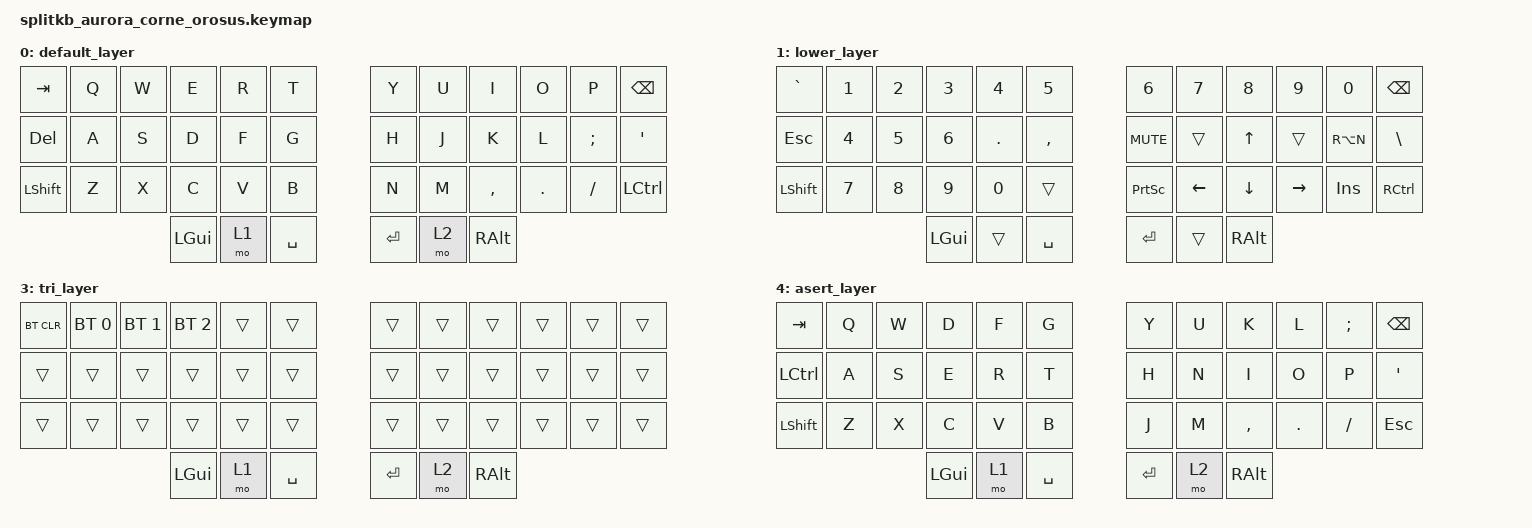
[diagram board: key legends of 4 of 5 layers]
/*
 * Copyright (c) 2020 The ZMK Contributors
 *
 * SPDX-License-Identifier: MIT
 */
 
// ------ Libraries ------------------------------------------------------------------------
#include <behaviors.dtsi>
#include <dt-bindings/zmk/keys.h>
#include <dt-bindings/zmk/outputs.h>
#include <dt-bindings/zmk/bt.h>

#define ___ &trans

// ------ main bracket ---------------------------------------------------------------------
/ {
    // -------------------------------------------------------------------------------------------------------------------------
    
    conditional_layers {
        compatible = "zmk,conditional-layers";
        tri_layer {
            if-layers = <1 2>;
            then-layer = <3>;
        };
    };
    
    // -------------------------------------------------------------------------------------------------------------------------
    keymap {
        compatible = "zmk,keymap";

        default_layer {
            bindings = <
// ┌─────────┬─────────┬─────────┬─────────┬─────────┬─────────┐   ┌─────────┬─────────┬─────────┬─────────┬─────────┬─────────┐ 
// |   TAB   |    Q    |    W    |    E    |    R    |    T    |   |    Y    |    U    |    I    |    O    |    P    |   BKSP  |
    &kp TAB   &kp Q     &kp W     &kp E     &kp R     &kp T         &kp Y     &kp U     &kp I     &kp O     &kp P     &kp BSPC
// ├─────────┼─────────┼─────────┼─────────┼─────────┼─────────┤   ├─────────┼─────────┼─────────┼─────────┼─────────┼─────────┤ 
// |  DEL    |    A    |    S    |    D    |    F    |    G    |   |    H    |    J    |    K    |    L    |    ;    |    '    |
   &kp DEL    &kp A     &kp S     &kp D     &kp F     &kp G         &kp H     &kp J     &kp K     &kp L     &kp SEMI  &kp SQT
// ├─────────┼─────────┼─────────┼─────────┼─────────┼─────────┤   ├─────────┼─────────┼─────────┼─────────┼─────────┼─────────┤ 
// |  SHFT   |    Z    |    X    |    C    |    V    |    B    |   |    N    |    M    |    ,    |    .    |    /    |   CTRL  |
   &kp LSHFT  &kp Z     &kp X     &kp C     &kp V     &kp B         &kp N     &kp M     &kp COMMA  &kp DOT   &kp FSLH  &kp LCTRL
// └─────────┴─────────┴─────────┼─────────┼─────────┼─────────┤   ├─────────┼─────────┼─────────┼─────────┴─────────┴─────────┘ 
//                               |   GUI   |  LOWER  |  SPACE  |   |  ENTER  |  RAISE  |   ALT   |
                                  &kp LGUI  &mo 1     &kp SPACE     &kp RET   &mo 2     &kp RALT
//                               └─────────┴─────────┴─────────┘   └─────────┴─────────┴─────────┘
            >;
        };
        lower_layer {
            bindings = <
// ┌─────────┬─────────┬─────────┬─────────┬─────────┬─────────┐   ┌─────────┬─────────┬─────────┬─────────┬─────────┬─────────┐ 
// |    `    |    1    |    2    |    3    |    4    |    5    |   |    6    |    7    |    8    |    9    |    0    |   BKSP  |
   &kp GRAVE  &kp N1    &kp N2    &kp N3    &kp N4    &kp N5        &kp N6    &kp N7    &kp N8    &kp N9    &kp N0    &kp BSPC
// ├─────────┼─────────┼─────────┼─────────┼─────────┼─────────┤   ├─────────┼─────────┼─────────┼─────────┼─────────┼─────────┤ 
// |   ESC   |    4    |    5    |    6    |    .    |    ,    |   |  Mute   |  VOL-   |   UP    |  VOL+   |    Ñ    |    \    |
    &kp ESC   &kp N4    &kp N5    &kp N6    &kp DOT   &kp COMMA     &kp MUTE   &trans    &kp UP    &trans  &kp RA(N) &kp BSLH 
// ├─────────┼─────────┼─────────┼─────────┼─────────┼─────────┤   ├─────────┼─────────┼─────────┼─────────┼─────────┼─────────┤ 
// |   SHFT  |    7    |    8    |    9    |    0    |    €    |   | PrnScrn |   LFT   |  DWN    |   RGT   | INSERT  |   CTRL  |
    &kp LSHFT  &kp N7   &kp N8    &kp N9    &kp N0     &trans      &kp PSCRN  &kp LEFT  &kp DOWN &kp RIGHT  &kp INS   &kp RCTRL
// └─────────┴─────────┴─────────┼─────────┼─────────┼─────────┤   ├─────────┼─────────┼─────────┼─────────┴─────────┴─────────┘ 
//                               |   GUI   |         |   SPC   |   |   ENT   |         |   ALT   |
                          	      &kp LGUI     ___    &kp SPACE    &kp RET       ___    &kp RALT
//                               └─────────┴─────────┴─────────┘   └─────────┴─────────┴─────────┘
            >;
        };
        raise_layer {
            bindings = <
// ┌─────────┬─────────┬─────────┬─────────┬─────────┬─────────┐   ┌─────────┬─────────┬─────────┬─────────┬─────────┬─────────┐ 
// |    ~    |    !    |    @    |    #    |    $    |    %    |   |    ^    |    &    |    *    |    (    |    )    |   BKSP  |
    &kp TILDE  &kp EXCL  &kp AT   &kp HASH   &kp DLLR  &kp PRCNT     &kp CARET &kp AMPS  &kp ASTRK &kp LPAR  &kp RPAR  &kp BSPC
// ├─────────┼─────────┼─────────┼─────────┼─────────┼─────────┤   ├─────────┼─────────┼─────────┼─────────┼─────────┼─────────┤ 
// |    ESC  |    F1   |   F2    |   F3    |   F4    |   F5    |   |   F6    |    -    |    =    |    [    |    ]    |   "|"   |
    &kp ESC   &kp F1    &kp F2    &kp F3    &kp F4    &kp F5        &kp F6    &kp MINUS &kp EQUAL &kp LBKT  &kp RBKT  &kp PIPE
// ├─────────┼─────────┼─────────┼─────────┼─────────┼─────────┤   ├─────────┼─────────┼─────────┼─────────┼─────────┼─────────┤ 
// |   SHFT  |    F7   |   F8    |   F9    |   F10   |   F11   |   |   F12   |    _    |    +    |    {    |    }    |    ~    |
    &kp LSHF T&kp F7    &kp F8    &kp F9    &kp F10    &kp F11      &kp F12   &kp UNDER &kp PLUS  &kp LBRC  &kp RBRC  &kp RCTRL
// └─────────┴─────────┴─────────┼─────────┼─────────┼─────────┤   ├─────────┼─────────┼─────────┼─────────┴─────────┴─────────┘ 
//                               |   GUI   |         |  SPACE  |   |  ENTER  |         |   ALT   |
                          	      &kp LGUI     ___    &kp SPACE    &kp RET       ___    &kp RALT
//                               └─────────┴─────────┴─────────┘   └─────────┴─────────┴─────────┘
            >;
        };
        tri_layer {
            bindings = <
// ┌─────────┬─────────┬─────────┬─────────┬─────────┬─────────┐   ┌─────────┬─────────┬─────────┬─────────┬─────────┬─────────┐ 
// |  BTCLR  |  BT1    |  BT2    |  BT3    |         |         |   |         |         |         |         |         |TO QWERTY|
&bt BT_CLR &bt BT_SEL 0 &bt BT_SEL 1 &bt BT_SEL 2 ___     ___          ___       ___       ___       ___       ___       ___  
// ├─────────┼─────────┼─────────┼─────────┼─────────┼─────────┤   ├─────────┼─────────┼─────────┼─────────┼─────────┼─────────┤ 
// |         |         | MS_BTN1 |  WH_UP  | MS_BTN2 |         |   |  Play   |  Prev   | MOUSEUP |  Next   |         |TO ASERT |
       ___       ___       ___       ___       ___       ___            ___       ___       ___       ___       ___       ___   
// ├─────────┼─────────┼─────────┼─────────┼─────────┼─────────┤   ├─────────┼─────────┼─────────┼─────────┼─────────┼─────────┤ 
// |         |         |         |  WH_DO  |         |         |   |  Stop   | MOUSERI | MOUSEDO | MOUSELE |         |         |
       ___       ___       ___       ___       ___       ___            ___       ___       ___       ___       ___       ___    
// └─────────┴─────────┴─────────┼─────────┼─────────┼─────────┤   ├─────────┼─────────┼─────────┼─────────┴─────────┴─────────┘ 
//                               |   GUI   |  LOWER  |  SPACE  |   |  ENTER  |  RAISE  |   ALT   |
                                  &kp LGUI  &mo 1     &kp SPACE     &kp RET   &mo 2     &kp RALT
//                               └─────────┴─────────┴─────────┘   └─────────┴─────────┴─────────┘
            >;
        };
        asert_layer {
             bindings = <
// ┌─────────┬─────────┬─────────┬─────────┬─────────┬─────────┐   ┌─────────┬─────────┬─────────┬─────────┬─────────┬─────────┐ 
// |   TAB   |    Q    |    W    |    D    |    F    |    G    |   |    Y    |    U    |    K    |    L    |    ;    |   BKSP  |
    &kp TAB   &kp Q     &kp W     &kp D     &kp F     &kp G         &kp Y     &kp U     &kp K     &kp L     &kp SEMI   &kp BSPC
// ├─────────┼─────────┼─────────┼─────────┼─────────┼─────────┤   ├─────────┼─────────┼─────────┼─────────┼─────────┼─────────┤ 
// |  CTRL   |    A    |    S    |    E    |    R    |    T    |   |    H    |    N    |    I    |    O    |    P    |    '    |
   &kp LCTRL  &kp A     &kp S     &kp E     &kp R     &kp T         &kp H     &kp N     &kp I     &kp O     &kp P      &kp SQT
// ├─────────┼─────────┼─────────┼─────────┼─────────┼─────────┤   ├─────────┼─────────┼─────────┼─────────┼─────────┼─────────┤ 
// |  SHFT   |    Z    |    X    |    C    |    V    |    B    |   |    J    |    M    |    ,    |    .    |    /    |   ESC   |
   &kp LSHFT  &kp Z     &kp X     &kp C     &kp V     &kp B         &kp J     &kp M     &kp COMMA  &kp DOT   &kp FSLH  &kp ESC
// └─────────┴─────────┴─────────┼─────────┼─────────┼─────────┤   ├─────────┼─────────┼─────────┼─────────┴─────────┴─────────┘ 
//                               |   GUI   |  LOWER  |  SPACE  |   |  ENTER  |  RAISE  |   ALT   |
                                  &kp LGUI  &mo 1     &kp SPACE     &kp RET   &mo 2     &kp RALT
//                               └─────────┴─────────┴─────────┘   └─────────┴─────────┴─────────┘
            >;
        };
    }; 
    // ------ keymap bracket ends
}; 
// ------- main bracket ends

// ------------------- HELP NOTES -----------------------------------------------------------
//
// &kp: key pressed (used for normal keys)
// &bt: bluetooth function
// &mo: momentary layout change (only while key is holded)
// &ht: hold-tap will output the 1st key if it's held for a while, and output the 2nd when it's tapped quickly
// &tog: switches to layer number and we keep staying on that new label
// 
// Letter frequency:
// EN: ETAOINSHRDLCUMWFGYPBVKJXQZ
// ES: AEOSRNILDUTCMPBGVYQHFJZÑXWK
//

